# STM32L462VET6 register map
File version: 1.0
Registers are 32-bit, access not given, reset 0x0 unless marked. A register's access mark holds for its fields unless they carry their own. Offsets are from the block's base; [hi:lo] are bit positions; {n}, {i} and the like mark numbered series; 'fields as' and 'values as' point back to an identical list.

## DFSDM1
Base 0x40016000
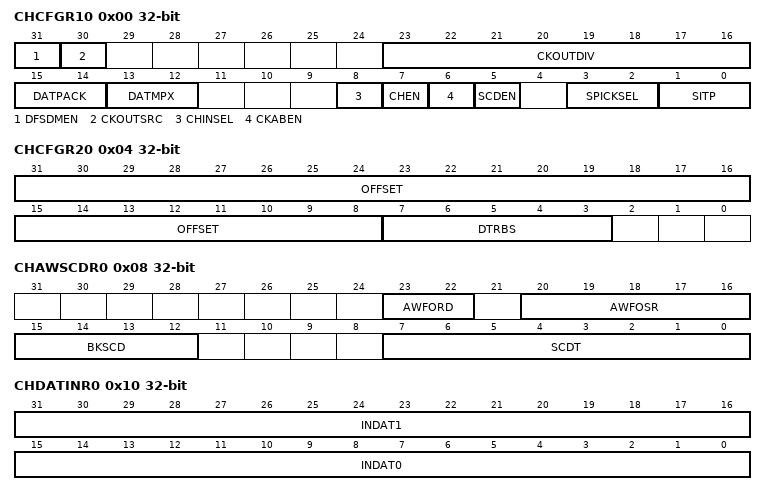
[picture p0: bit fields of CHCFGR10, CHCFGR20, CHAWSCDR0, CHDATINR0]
0x00 CHCFGR10
  [31] DFSDMEN, [30] CKOUTSRC, [23:16] CKOUTDIV, [15:14] DATPACK, [13:12] DATMPX, [8] CHINSEL, [7] CHEN, [6] CKABEN, [5] SCDEN, [3:2] SPICKSEL, [1:0] SITP
0x04 CHCFGR20
  [31:8] OFFSET, [7:3] DTRBS
0x08 CHAWSCDR0
  [23:22] AWFORD, [20:16] AWFOSR, [15:12] BKSCD, [7:0] SCDT
0x0C CHWDATAR0
0x10 CHDATINR0
  [31:16] INDAT1, [15:0] INDAT0
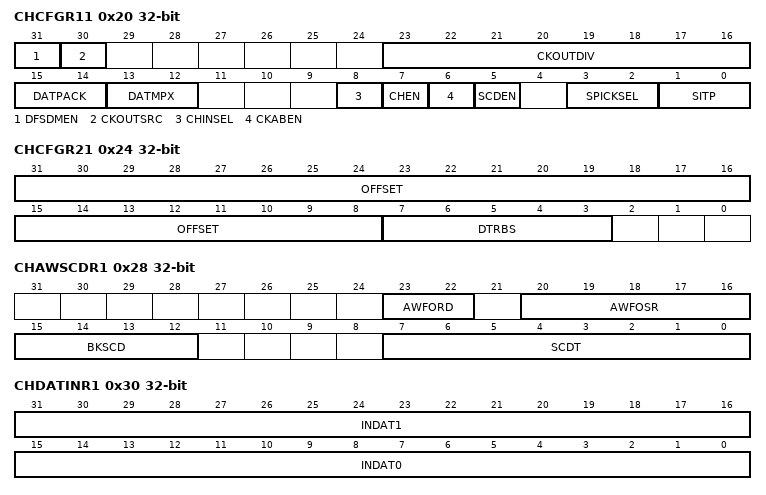
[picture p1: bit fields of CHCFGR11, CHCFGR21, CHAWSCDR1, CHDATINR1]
0x20 CHCFGR11
  fields as CHCFGR10
0x24 CHCFGR21
  [31:8] OFFSET, [7:3] DTRBS
0x28 CHAWSCDR1
  [23:22] AWFORD, [20:16] AWFOSR, [15:12] BKSCD, [7:0] SCDT
0x2C CHWDATAR1
0x30 CHDATINR1
  [31:16] INDAT1, [15:0] INDAT0
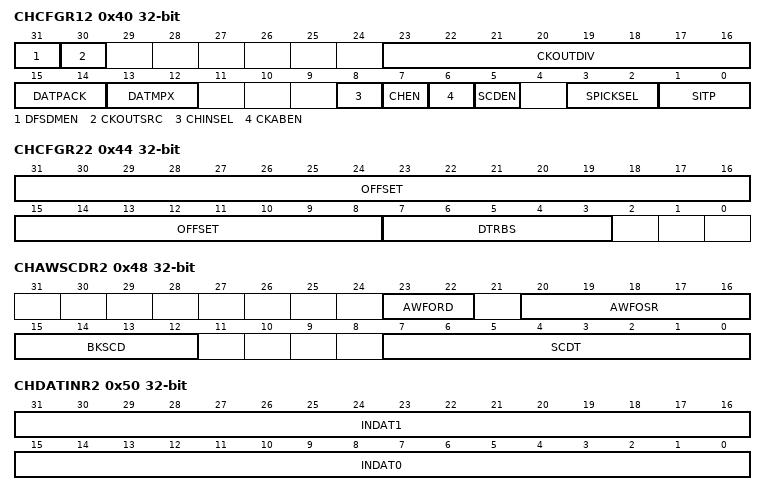
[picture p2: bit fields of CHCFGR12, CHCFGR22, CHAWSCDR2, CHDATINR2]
0x40 CHCFGR12
  fields as CHCFGR10
0x44 CHCFGR22
  [31:8] OFFSET, [7:3] DTRBS
0x48 CHAWSCDR2
  [23:22] AWFORD, [20:16] AWFOSR, [15:12] BKSCD, [7:0] SCDT
0x4C CHWDATAR2
0x50 CHDATINR2
  [31:16] INDAT1, [15:0] INDAT0
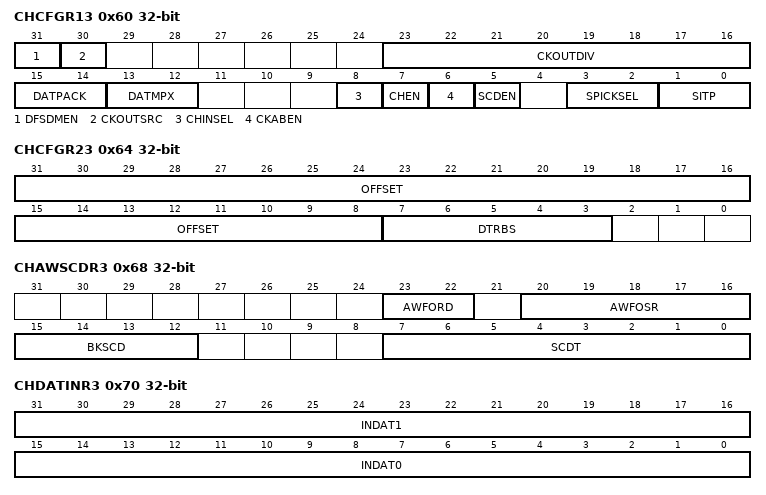
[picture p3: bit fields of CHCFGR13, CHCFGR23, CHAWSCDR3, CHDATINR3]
0x60 CHCFGR13
  fields as CHCFGR10
0x64 CHCFGR23
  [31:8] OFFSET, [7:3] DTRBS
0x68 CHAWSCDR3
  [23:22] AWFORD, [20:16] AWFOSR, [15:12] BKSCD, [7:0] SCDT
0x6C CHWDATAR3
0x70 CHDATINR3
  [31:16] INDAT1, [15:0] INDAT0
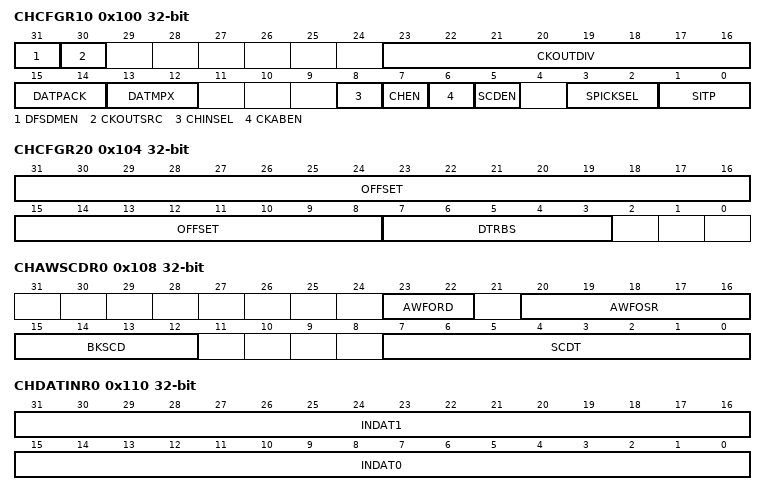
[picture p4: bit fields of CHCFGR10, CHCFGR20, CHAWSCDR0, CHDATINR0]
0x100 CHCFGR10
  fields as CHCFGR10
0x104 CHCFGR20
  [31:8] OFFSET, [7:3] DTRBS
0x108 CHAWSCDR0
  [23:22] AWFORD, [20:16] AWFOSR, [15:12] BKSCD, [7:0] SCDT
0x10C CHWDATAR0
0x110 CHDATINR0
  [31:16] INDAT1, [15:0] INDAT0
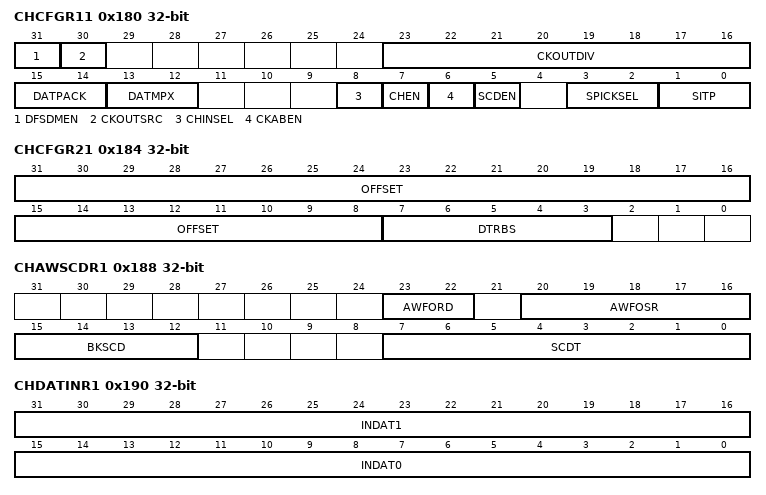
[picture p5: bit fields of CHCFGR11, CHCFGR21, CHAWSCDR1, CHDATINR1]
0x180 CHCFGR11
  fields as CHCFGR10
0x184 CHCFGR21
  [31:8] OFFSET, [7:3] DTRBS
0x188 CHAWSCDR1
  [23:22] AWFORD, [20:16] AWFOSR, [15:12] BKSCD, [7:0] SCDT
0x18C CHWDATAR1
0x190 CHDATINR1
  [31:16] INDAT1, [15:0] INDAT0

## DMA1
Base 0x40020000
Same registers: DMA2 0x40020400
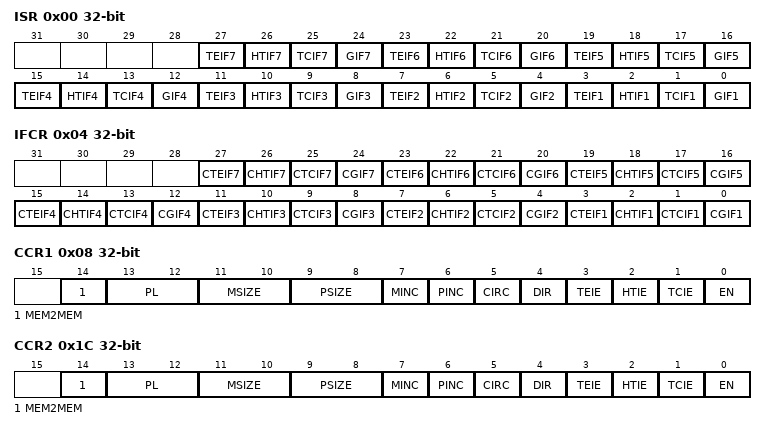
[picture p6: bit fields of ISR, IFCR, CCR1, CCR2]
0x00 ISR
  [4n-1] TEIF{n} (n=1..7), [4n-2] HTIF{n} (n=1..7), [4n-3] TCIF{n} (n=1..7), [4n-4] GIF{n} (n=1..7)
0x04 IFCR
  [4n-1] CTEIF{n} (n=1..7), [4n-2] CHTIF{n} (n=1..7), [4n-3] CTCIF{n} (n=1..7), [4n-4] CGIF{n} (n=1..7)
0x08 CCR1
  [14] MEM2MEM, [13:12] PL, [11:10] MSIZE, [9:8] PSIZE, [7] MINC, [6] PINC, [5] CIRC, [4] DIR, [3] TEIE, [2] HTIE, [1] TCIE, [0] EN
0x0C CNDTR1
  [15:0] NDT
0x10 CPAR1
  [31:0] PA
{0x0+0x14*i} CMAR{i} (i=1..7)
  [31:0] MA
0x1C CCR2
  fields as CCR1
0x20 CNDTR2
  [15:0] NDT
0x24 CPAR2
  [31:0] PA
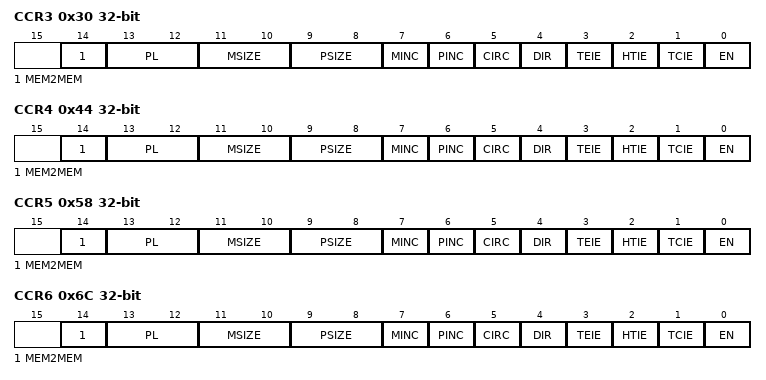
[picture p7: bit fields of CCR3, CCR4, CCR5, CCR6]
0x30 CCR3
  fields as CCR1
0x34 CNDTR3
  [15:0] NDT
0x38 CPAR3
  [31:0] PA
0x44 CCR4
  fields as CCR1
0x48 CNDTR4
  [15:0] NDT
0x4C CPAR4
  [31:0] PA
0x58 CCR5
  fields as CCR1
0x5C CNDTR5
  [15:0] NDT
0x60 CPAR5
  [31:0] PA
0x6C CCR6
  fields as CCR1
0x70 CNDTR6
  [15:0] NDT
0x74 CPAR6
  [31:0] PA
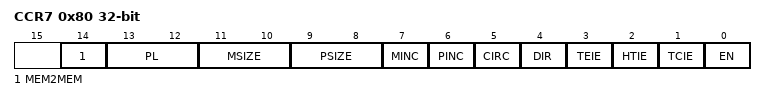
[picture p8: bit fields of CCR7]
0x80 CCR7
  fields as CCR1
0x84 CNDTR7
  [15:0] NDT
0x88 CPAR7
  [31:0] PA

## DMA1_CSELR
Base 0x400200A8
Same registers: DMA2_CSELR 0x400204A8
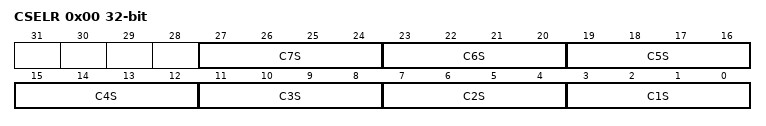
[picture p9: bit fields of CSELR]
0x00 CSELR
  [4n-1:4n-4] C{n}S (n=1..7)

## FLASH
Base 0x40022000
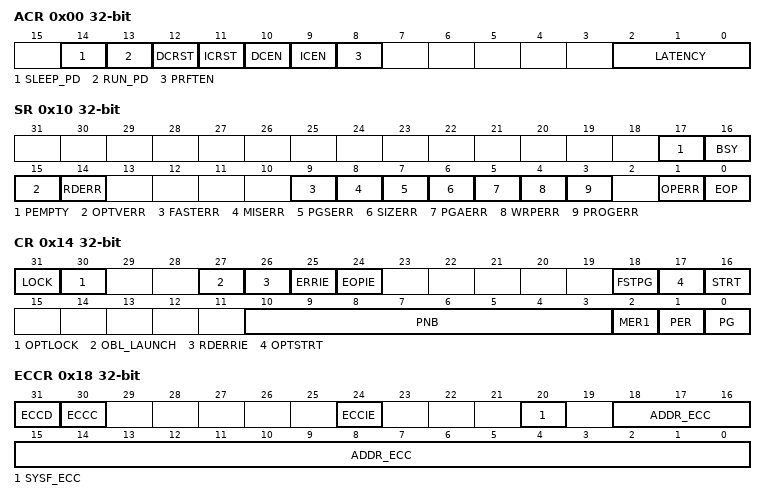
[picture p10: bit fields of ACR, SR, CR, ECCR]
0x00 ACR
  [14] SLEEP_PD, [13] RUN_PD, [12] DCRST, [11] ICRST, [10] DCEN, [9] ICEN, [8] PRFTEN, [2:0] LATENCY
0x04 PDKEYR
0x08 KEYR
0x0C OPTKEYR
0x10 SR
  [17] PEMPTY, [16] BSY, [15] OPTVERR, [14] RDERR, [9] FASTERR, [8] MISERR, [7] PGSERR, [6] SIZERR, [5] PGAERR, [4] WRPERR, [3] PROGERR, [1] OPERR, [0] EOP
0x14 CR
  [31] LOCK, [30] OPTLOCK, [27] OBL_LAUNCH, [26] RDERRIE, [25] ERRIE, [24] EOPIE, [18] FSTPG, [17] OPTSTRT, [16] STRT, [10:3] PNB, [2] MER1, [1] PER, [0] PG
0x18 ECCR
  [31] ECCD, [30] ECCC, [24] ECCIE, [20] SYSF_ECC, [18:0] ADDR_ECC
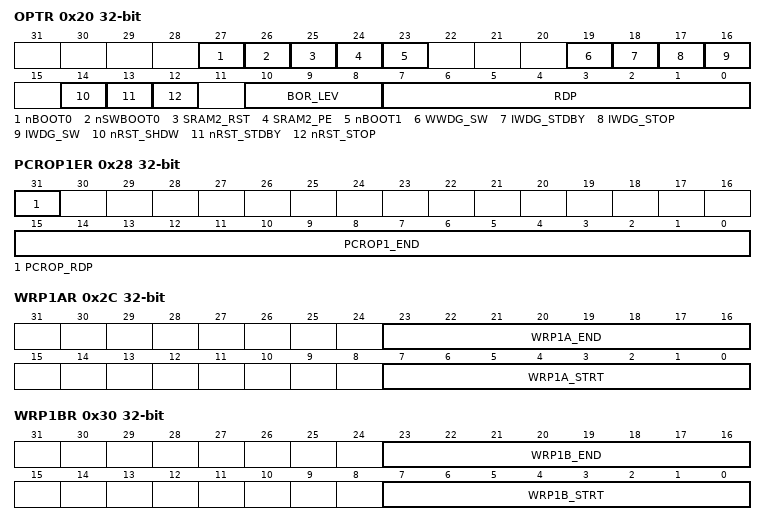
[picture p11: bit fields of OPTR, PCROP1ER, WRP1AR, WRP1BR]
0x20 OPTR
  [27] nBOOT0, [26] nSWBOOT0, [25] SRAM2_RST, [24] SRAM2_PE, [23] nBOOT1, [19] WWDG_SW, [18] IWDG_STDBY, [17] IWDG_STOP, [16] IWDG_SW, [14] nRST_SHDW, [13] nRST_STDBY, [12] nRST_STOP, [10:8] BOR_LEV, [7:0] RDP
0x24 PCROP1SR
  [15:0] PCROP1_STRT
0x28 PCROP1ER
  [31] PCROP_RDP, [15:0] PCROP1_END
0x2C WRP1AR
  [23:16] WRP1A_END, [7:0] WRP1A_STRT
0x30 WRP1BR
  [23:16] WRP1B_END, [7:0] WRP1B_STRT

## CRC
Base 0x40023000
0x00 DR
0x04 IDR 8-bit
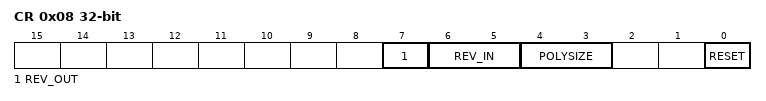
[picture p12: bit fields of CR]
0x08 CR
  [7] REV_OUT, [6:5] REV_IN, [4:3] POLYSIZE, [0] RESET
0x10 INIT
0x14 POL
